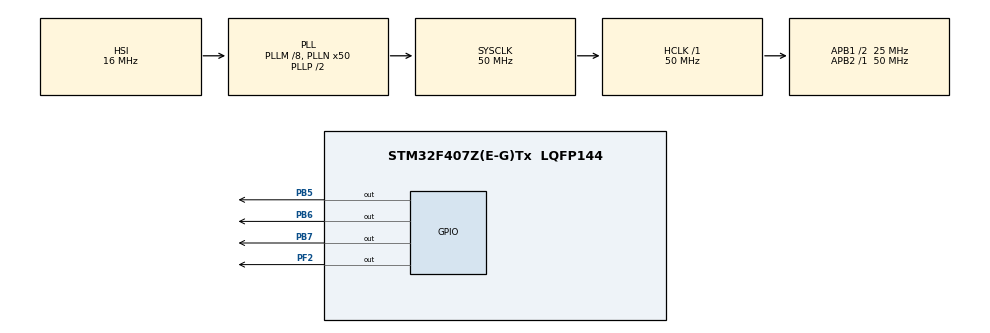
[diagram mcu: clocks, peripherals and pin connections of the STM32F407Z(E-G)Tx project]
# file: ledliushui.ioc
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Mcu.Family=STM32F4
Mcu.Name=STM32F407Z(E-G)Tx
Mcu.Package=LQFP144
NVIC.PriorityGroup=NVIC_PRIORITYGROUP_4
PA13.Mode=Serial_Wire
PA13.Signal=SYS_JTMS-SWDIO
PA14.Mode=Serial_Wire
PA14.Signal=SYS_JTCK-SWCLK
PB5.PinState=GPIO_PIN_SET
PB5.Signal=GPIO_Output
PB6.PinState=GPIO_PIN_SET
PB6.Signal=GPIO_Output
PB7.PinState=GPIO_PIN_SET
PB7.Signal=GPIO_Output
PC14-OSC32_IN.Mode=LSE-External-Oscillator
PC14-OSC32_IN.Signal=RCC_OSC32_IN
PC15-OSC32_OUT.Mode=LSE-External-Oscillator
PC15-OSC32_OUT.Signal=RCC_OSC32_OUT
PF2.PinState=GPIO_PIN_SET
PF2.Signal=GPIO_Output
PH0-OSC_IN.Mode=HSE-External-Oscillator
PH0-OSC_IN.Signal=RCC_OSC_IN
PH1-OSC_OUT.Mode=HSE-External-Oscillator
PH1-OSC_OUT.Signal=RCC_OSC_OUT
ProjectManager.HeapSize=0x200
ProjectManager.StackSize=0x400
ProjectManager.TargetToolchain=MDK-ARM V5.32
RCC.48MHZClocksFreq_Value=25000000
RCC.AHBFreq_Value=50000000
RCC.APB1CLKDivider=RCC_HCLK_DIV2
RCC.APB1Freq_Value=25000000
RCC.APB1TimFreq_Value=50000000
RCC.APB2Freq_Value=50000000
RCC.APB2TimFreq_Value=50000000
RCC.CortexFreq_Value=50000000
RCC.HCLKFreq_Value=50000000
RCC.HSE_VALUE=25000000
RCC.HSI_VALUE=16000000
RCC.PLLM=8
RCC.PLLN=50
RCC.SYSCLKFreq_VALUE=50000000
RCC.SYSCLKSource=RCC_SYSCLKSOURCE_PLLCLK
RCC.VCOOutputFreq_Value=100000000
board=custom

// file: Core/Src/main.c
/* USER CODE BEGIN Includes */
#include "stm32f4xx_hal.h"
/* USER CODE END Includes */

/* USER CODE BEGIN PFP */
extern void asm_init_ports(void);
extern void asm_set_pin_led(uint16_t pin);
extern void asm_reset_pin_led(uint16_t pin);
extern void asm_set_pin_beep(uint16_t pin);
extern void asm_reset_pin_beep(uint16_t pin);
/* USER CODE END PFP */

void SystemClock_Config(void);
void Error_Handler(void);

int main(void)
{
    /* MCU Configuration--------------------------------------------------------*/
    HAL_Init();
    SystemClock_Config();
    asm_init_ports();  // ??????????

		// beep for 1s
		asm_set_pin_beep(4);   // Set PA5
		HAL_Delay(1000);
		asm_reset_pin_beep(4); // Reset PA5

    while (1)
    {
        /* Running water lamps */
        asm_set_pin_led(4);   // Set PB5
        HAL_Delay(1000);
        asm_reset_pin_led(4); // Reset PB5

        asm_set_pin_led(5);   // Set PB6
        HAL_Delay(1000);
        asm_reset_pin_led(5); // Reset PB6

        asm_set_pin_led(6);   // Set PB7
        HAL_Delay(1000);
        asm_reset_pin_led(6); // Reset PB7
				HAL_Delay(1000);
    }
}

void SystemClock_Config(void)
{
  RCC_OscInitTypeDef RCC_OscInitStruct = {0};
  RCC_ClkInitTypeDef RCC_ClkInitStruct = {0};

  /** Configure the main internal regulator output voltage
  */
  __HAL_RCC_PWR_CLK_ENABLE();
  __HAL_PWR_VOLTAGESCALING_CONFIG(PWR_REGULATOR_VOLTAGE_SCALE1);

  /** Initializes the RCC Oscillators according to the specified parameters
  * in the RCC_OscInitTypeDef structure.
  */
  RCC_OscInitStruct.OscillatorType = RCC_OSCILLATORTYPE_HSI;
  RCC_OscInitStruct.HSIState = RCC_HSI_ON;
  RCC_OscInitStruct.HSICalibrationValue = RCC_HSICALIBRATION_DEFAULT;
  RCC_OscInitStruct.PLL.PLLState = RCC_PLL_ON;
  RCC_OscInitStruct.PLL.PLLSource = RCC_PLLSOURCE_HSI;
  RCC_OscInitStruct.PLL.PLLM = 8;
  RCC_OscInitStruct.PLL.PLLN = 50;
  RCC_OscInitStruct.PLL.PLLP = RCC_PLLP_DIV2;
  RCC_OscInitStruct.PLL.PLLQ = 4;
  if (HAL_RCC_OscConfig(&RCC_OscInitStruct) != HAL_OK)
  {
    Error_Handler();
  }

  /** Initializes the CPU, AHB and APB buses clocks
  */
  RCC_ClkInitStruct.ClockType = RCC_CLOCKTYPE_HCLK|RCC_CLOCKTYPE_SYSCLK
                              |RCC_CLOCKTYPE_PCLK1|RCC_CLOCKTYPE_PCLK2;
  RCC_ClkInitStruct.SYSCLKSource = RCC_SYSCLKSOURCE_PLLCLK;
  RCC_ClkInitStruct.AHBCLKDivider = RCC_SYSCLK_DIV1;
  RCC_ClkInitStruct.APB1CLKDivider = RCC_HCLK_DIV2;
  RCC_ClkInitStruct.APB2CLKDivider = RCC_HCLK_DIV1;

  if (HAL_RCC_ClockConfig(&RCC_ClkInitStruct, FLASH_LATENCY_1) != HAL_OK)
  {
    Error_Handler();
  }
}

void Error_Handler(void)
{
  __disable_irq();
  while (1)
  {
  }
}
